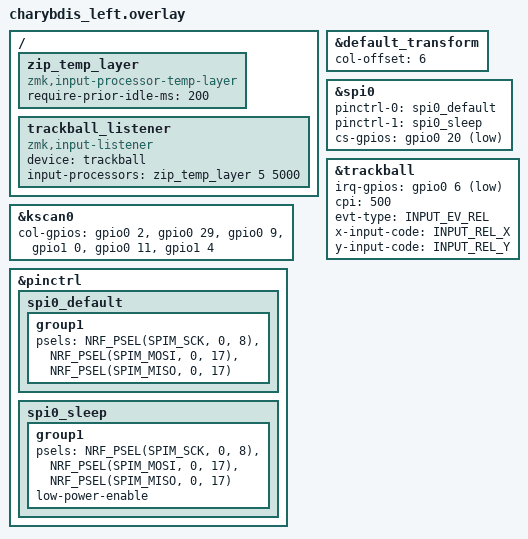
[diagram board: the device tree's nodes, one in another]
/*
 * Copyright (c) 2020 ZMK Contributors
 *
 * SPDX-License-Identifier: MIT
 */
 
#include "charybdis.dtsi"
#include <input/processors.dtsi>
#include <dt-bindings/zmk/matrix_transform.h>
#include <dt-bindings/pinctrl/nrf-pinctrl.h>
/* ★ トラックボールのプロパティ定義に必須 */
#include <dt-bindings/input/input-event-codes.h> 

&default_transform {
    col-offset = <6>;
};

&kscan0 {
    col-gpios
        = <&gpio0 2 (GPIO_ACTIVE_HIGH | GPIO_PULL_DOWN)>
        , <&gpio0 29 (GPIO_ACTIVE_HIGH | GPIO_PULL_DOWN)>
        , <&gpio0 9 (GPIO_ACTIVE_HIGH | GPIO_PULL_DOWN)>
        , <&gpio1 0  (GPIO_ACTIVE_HIGH | GPIO_PULL_DOWN)>
        , <&gpio0 11 (GPIO_ACTIVE_HIGH | GPIO_PULL_DOWN)>
        , <&gpio1 4  (GPIO_ACTIVE_HIGH | GPIO_PULL_DOWN)>
        ;
};

/* --- 新しい pinctrl 形式のSPI定義 --- */

&spi0 {
    status = "okay";
    pinctrl-0 = <&spi0_default>;
    pinctrl-1 = <&spi0_sleep>;
    pinctrl-names = "default", "sleep";
    cs-gpios = <&gpio0 20 GPIO_ACTIVE_LOW>;
};

&pinctrl {
    spi0_default: spi0_default {
        group1 {
            psels = <NRF_PSEL(SPIM_SCK, 0, 8)>,
                    <NRF_PSEL(SPIM_MOSI, 0, 17)>,
                    <NRF_PSEL(SPIM_MISO, 0, 17)>;
        };
    };

    spi0_sleep: spi0_sleep {
        group1 {
            psels = <NRF_PSEL(SPIM_SCK, 0, 8)>,
                    <NRF_PSEL(SPIM_MOSI, 0, 17)>,
                    <NRF_PSEL(SPIM_MISO, 0, 17)>;
            low-power-enable;
        };
    };
};

/* --- トラックボールの定義 (必須プロパティを追加) --- */
&trackball {
    status = "okay";
    irq-gpios = <&gpio0 6 (GPIO_ACTIVE_LOW | GPIO_PULL_UP)>;

    /* ★ エラー解消のためにこのブロックが必須 */
    cpi = <500>;
    evt-type = <INPUT_EV_REL>;
    x-input-code = <INPUT_REL_X>;
    y-input-code = <INPUT_REL_Y>;
};


/* --- AML（機能）定義 --- */

/ {
    zip_temp_layer: zip_temp_layer {
        compatible = "zmk,input-processor-temp-layer";
        #input-processor-cells = <2>;
        require-prior-idle-ms = <200>; 
    };

    trackball_listener: trackball_listener {
        compatible = "zmk,input-listener";
        device = <&trackball>;
        input-processors = <&zip_temp_layer 5 5000>; 
    };
};
